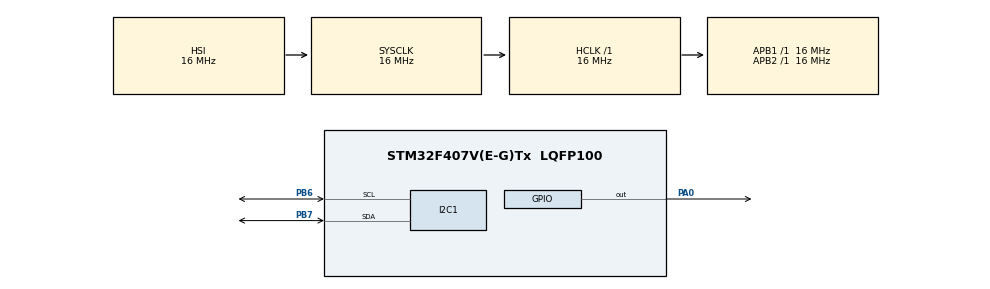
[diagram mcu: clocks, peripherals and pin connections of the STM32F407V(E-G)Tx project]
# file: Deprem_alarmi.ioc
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Mcu.Family=STM32F4
Mcu.Name=STM32F407V(E-G)Tx
Mcu.Package=LQFP100
NVIC.PriorityGroup=NVIC_PRIORITYGROUP_4
PA0-WKUP.Signal=GPIO_Output
PB6.Mode=I2C
PB6.Signal=I2C1_SCL
PB7.Mode=I2C
PB7.Signal=I2C1_SDA
ProjectManager.HeapSize=0x200
ProjectManager.StackSize=0x400
ProjectManager.TargetToolchain=STM32CubeIDE
RCC.AHBFreq_Value=16000000
RCC.APB1Freq_Value=16000000
RCC.APB2Freq_Value=16000000
RCC.CortexFreq_Value=16000000
RCC.HSE_VALUE=25000000
RCC.HSI_VALUE=16000000
RCC.LSE_VALUE=32768
RCC.SYSCLKFreq_VALUE=16000000
RCC.VCOOutputFreq_Value=192000000
board=custom

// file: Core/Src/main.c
/* USER CODE BEGIN Header */
/**
  ******************************************************************************
  * @file           : main.c
  * @brief          : Main program body
  ******************************************************************************
  * @attention
  *
  * Copyright (c) 2025 STMicroelectronics.
  * All rights reserved.
  *
  * This software is licensed under terms that can be found in the LICENSE file
  * in the root directory of this software component.
  * If no LICENSE file comes with this software, it is provided AS-IS.
  *
  ******************************************************************************
  */
/* USER CODE END Header */
#include "main.h"
#include <math.h> // fabs() fonksiyonu için

#define MPU6050_ADDR (0x68 << 1) // 8-bit adres

I2C_HandleTypeDef hi2c1;

/* USER CODE BEGIN PV */
	float Ax, Ay, Az;
/* USER CODE END PV */

void SystemClock_Config(void);
static void MX_GPIO_Init(void);
static void MX_I2C1_Init(void);

/* USER CODE BEGIN PFP */
void MPU6050_Init(void);
void MPU6050_Read_Accel(float* Ax, float* Ay, float* Az);
/* USER CODE END PFP */

/* USER CODE BEGIN 0 */
void MPU6050_Init(void) {
    uint8_t check;
    uint8_t data;

    // WHO_AM_I register (0x75) -> 0x68 beklenir
    HAL_I2C_Mem_Read(&hi2c1, MPU6050_ADDR, 0x75, 1, &check, 1, HAL_MAX_DELAY);

    if (check == 104) {
        // Uyku modunu kapat (PWR_MGMT_1 = 0x6B, data=0)
        data = 0;
        HAL_I2C_Mem_Write(&hi2c1, MPU6050_ADDR, 0x6B, 1, &data, 1, HAL_MAX_DELAY);

        // Accelerometer ±2g ayarı (ACCEL_CONFIG = 0x1C, data=0)
        data = 0;
        HAL_I2C_Mem_Write(&hi2c1, MPU6050_ADDR, 0x1C, 1, &data, 1, HAL_MAX_DELAY);
    }
}

void MPU6050_Read_Accel(float* Ax, float* Ay, float* Az) {
    uint8_t Rec_Data[6];
    int16_t Accel_X_RAW, Accel_Y_RAW, Accel_Z_RAW;

    HAL_I2C_Mem_Read(&hi2c1, MPU6050_ADDR, 0x3B, 1, Rec_Data, 6, HAL_MAX_DELAY);

    Accel_X_RAW = (int16_t)(Rec_Data[0] << 8 | Rec_Data[1]);
    Accel_Y_RAW = (int16_t)(Rec_Data[2] << 8 | Rec_Data[3]);
    Accel_Z_RAW = (int16_t)(Rec_Data[4] << 8 | Rec_Data[5]);

    *Ax = Accel_X_RAW / 16384.0;
    *Ay = Accel_Y_RAW / 16384.0;
    *Az = Accel_Z_RAW / 16384.0;
}
/* USER CODE END 0 */

int main(void)
{

  /* MCU Configuration--------------------------------------------------------*/

  /* Reset of all peripherals, Initializes the Flash interface and the Systick. */
  HAL_Init();

  /* Configure the system clock */
  SystemClock_Config();

  /* Initialize all configured peripherals */
  MX_GPIO_Init();
  MX_I2C1_Init();
  /* USER CODE BEGIN 2 */
  MPU6050_Init();
  /* USER CODE END 2 */

  /* Infinite loop */
  while (1)
  {

    /* USER CODE BEGIN 3 */
    MPU6050_Read_Accel(&Ax, &Ay, &Az);

    if (Az > 0.25 || Az < 0.1) {
        HAL_GPIO_WritePin(GPIOA, GPIO_PIN_0, GPIO_PIN_SET); // Buzzer ON
    } else {
        HAL_GPIO_WritePin(GPIOA, GPIO_PIN_0, GPIO_PIN_RESET); // Buzzer OFF
    }

    HAL_Delay(200);
  }
  /* USER CODE END 3 */
}

void SystemClock_Config(void)
{
  RCC_OscInitTypeDef RCC_OscInitStruct = {0};
  RCC_ClkInitTypeDef RCC_ClkInitStruct = {0};

  /** Configure the main internal regulator output voltage
  */
  __HAL_RCC_PWR_CLK_ENABLE();
  __HAL_PWR_VOLTAGESCALING_CONFIG(PWR_REGULATOR_VOLTAGE_SCALE1);

  /** Initializes the RCC Oscillators according to the specified parameters
  * in the RCC_OscInitTypeDef structure.
  */
  RCC_OscInitStruct.OscillatorType = RCC_OSCILLATORTYPE_HSI;
  RCC_OscInitStruct.HSIState = RCC_HSI_ON;
  RCC_OscInitStruct.HSICalibrationValue = RCC_HSICALIBRATION_DEFAULT;
  RCC_OscInitStruct.PLL.PLLState = RCC_PLL_NONE;
  if (HAL_RCC_OscConfig(&RCC_OscInitStruct) != HAL_OK)
  {
    Error_Handler();
  }

  /** Initializes the CPU, AHB and APB buses clocks
  */
  RCC_ClkInitStruct.ClockType = RCC_CLOCKTYPE_HCLK|RCC_CLOCKTYPE_SYSCLK
                              |RCC_CLOCKTYPE_PCLK1|RCC_CLOCKTYPE_PCLK2;
  RCC_ClkInitStruct.SYSCLKSource = RCC_SYSCLKSOURCE_HSI;
  RCC_ClkInitStruct.AHBCLKDivider = RCC_SYSCLK_DIV1;
  RCC_ClkInitStruct.APB1CLKDivider = RCC_HCLK_DIV1;
  RCC_ClkInitStruct.APB2CLKDivider = RCC_HCLK_DIV1;

  if (HAL_RCC_ClockConfig(&RCC_ClkInitStruct, FLASH_LATENCY_0) != HAL_OK)
  {
    Error_Handler();
  }
}

static void MX_I2C1_Init(void)
{

  hi2c1.Instance = I2C1;
  hi2c1.Init.ClockSpeed = 100000;
  hi2c1.Init.DutyCycle = I2C_DUTYCYCLE_2;
  hi2c1.Init.OwnAddress1 = 0;
  hi2c1.Init.AddressingMode = I2C_ADDRESSINGMODE_7BIT;
  hi2c1.Init.DualAddressMode = I2C_DUALADDRESS_DISABLE;
  hi2c1.Init.OwnAddress2 = 0;
  hi2c1.Init.GeneralCallMode = I2C_GENERALCALL_DISABLE;
  hi2c1.Init.NoStretchMode = I2C_NOSTRETCH_DISABLE;
  if (HAL_I2C_Init(&hi2c1) != HAL_OK)
  {
    Error_Handler();
  }

}

static void MX_GPIO_Init(void)
{
  GPIO_InitTypeDef GPIO_InitStruct = {0};

  /* GPIO Ports Clock Enable */
  __HAL_RCC_GPIOA_CLK_ENABLE();
  __HAL_RCC_GPIOB_CLK_ENABLE();

  /*Configure GPIO pin Output Level */
  HAL_GPIO_WritePin(GPIOA, GPIO_PIN_0, GPIO_PIN_RESET);

  /*Configure GPIO pin : PA0 */
  GPIO_InitStruct.Pin = GPIO_PIN_0;
  GPIO_InitStruct.Mode = GPIO_MODE_OUTPUT_PP;
  GPIO_InitStruct.Pull = GPIO_NOPULL;
  GPIO_InitStruct.Speed = GPIO_SPEED_FREQ_LOW;
  HAL_GPIO_Init(GPIOA, &GPIO_InitStruct);

}

void Error_Handler(void)
{
  __disable_irq();
  while (1)
  {
  }
}
